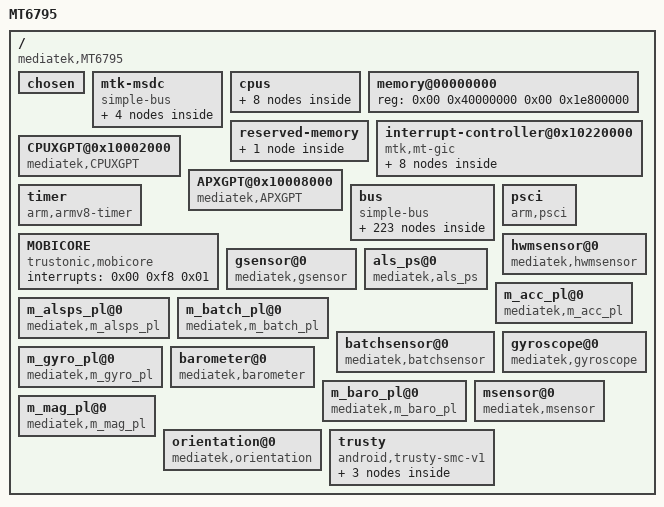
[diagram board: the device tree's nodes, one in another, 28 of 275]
/dts-v1/;

/ {
	model = "MT6795";
	compatible = "mediatek,MT6795";
	interrupt-parent = < 0x01 >;
	#address-cells = < 0x02 >;
	#size-cells = < 0x02 >;

	chosen {
		bootargs = "console=tty0 console=ttyMT0,921600n1 root=/dev/ram initrd=0x44000000,0x300000 loglevel=8";
	};

	mtk-msdc {
		compatible = "simple-bus";
		#address-cells = < 0x01 >;
		#size-cells = < 0x01 >;
		ranges = < 0x00 0x00 0x00 0xffffffff >;

		MSDC0@0x11230000 {
			compatible = "mediatek,MSDC0";
			reg = < 0x11230000 0x10000 0x10001e84 0x02 >;
			interrupts = < 0x00 0x4f 0x08 >;
		};

		MSDC1@0x11240000 {
			compatible = "mediatek,MSDC1";
			reg = < 0x11240000 0x10000 0x10001e84 0x02 >;
			interrupts = < 0x00 0x50 0x08 >;
		};

		MSDC2@0x11250000 {
			compatible = "mediatek,MSDC2";
			reg = < 0x11250000 0x10000 0x10001e84 0x02 >;
			interrupts = < 0x00 0x51 0x08 >;
		};

		MSDC3@0x11260000 {
			compatible = "mediatek,MSDC3";
			reg = < 0x11260000 0x10000 0x10001e84 0x02 >;
			interrupts = < 0x00 0x52 0x08 >;
		};
	};

	cpus {
		#address-cells = < 0x01 >;
		#size-cells = < 0x00 >;

		cpu@0 {
			device_type = "cpu";
			compatible = "arm,cortex-a53";
			reg = < 0x00 >;
			enable-method = "mt-boot";
			cpu-release-addr = < 0x00 0x40000200 >;
			clock-frequency = < 0x77359400 >;
			linux,phandle = < 0x02 >;
			phandle = < 0x02 >;
		};

		cpu@1 {
			device_type = "cpu";
			compatible = "arm,cortex-a53";
			reg = < 0x01 >;
			enable-method = "mt-boot";
			cpu-release-addr = < 0x00 0x40000200 >;
			clock-frequency = < 0x77359400 >;
			linux,phandle = < 0x03 >;
			phandle = < 0x03 >;
		};

		cpu@2 {
			device_type = "cpu";
			compatible = "arm,cortex-a53";
			reg = < 0x02 >;
			enable-method = "mt-boot";
			cpu-release-addr = < 0x00 0x40000200 >;
			clock-frequency = < 0x77359400 >;
			linux,phandle = < 0x04 >;
			phandle = < 0x04 >;
		};

		cpu@3 {
			device_type = "cpu";
			compatible = "arm,cortex-a53";
			reg = < 0x03 >;
			enable-method = "mt-boot";
			cpu-release-addr = < 0x00 0x40000200 >;
			clock-frequency = < 0x77359400 >;
			linux,phandle = < 0x05 >;
			phandle = < 0x05 >;
		};

		cpu@4 {
			device_type = "cpu";
			compatible = "arm,cortex-a53";
			reg = < 0x100 >;
			enable-method = "mt-boot";
			cpu-release-addr = < 0x00 0x40000200 >;
			clock-frequency = < 0x77359400 >;
			linux,phandle = < 0x06 >;
			phandle = < 0x06 >;
		};

		cpu@5 {
			device_type = "cpu";
			compatible = "arm,cortex-a53";
			reg = < 0x101 >;
			enable-method = "mt-boot";
			cpu-release-addr = < 0x00 0x40000200 >;
			clock-frequency = < 0x77359400 >;
			linux,phandle = < 0x07 >;
			phandle = < 0x07 >;
		};

		cpu@6 {
			device_type = "cpu";
			compatible = "arm,cortex-a53";
			reg = < 0x102 >;
			enable-method = "mt-boot";
			cpu-release-addr = < 0x00 0x40000200 >;
			clock-frequency = < 0x77359400 >;
			linux,phandle = < 0x08 >;
			phandle = < 0x08 >;
		};

		cpu@7 {
			device_type = "cpu";
			compatible = "arm,cortex-a53";
			reg = < 0x103 >;
			enable-method = "mt-boot";
			cpu-release-addr = < 0x00 0x40000200 >;
			clock-frequency = < 0x77359400 >;
			linux,phandle = < 0x09 >;
			phandle = < 0x09 >;
		};
	};

	memory@00000000 {
		device_type = "memory";
		reg = < 0x00 0x40000000 0x00 0x1e800000 >;
	};

	reserved-memory {
		#address-cells = < 0x02 >;
		#size-cells = < 0x02 >;
		ranges;

		reserve-memory-ccci_md1 {
			compatible = "reserve-memory-ccci_md1";
			no-map;
			size = < 0x00 0x5200000 >;
			alignment = < 0x00 0x2000000 >;
			alloc-ranges = < 0x00 0x40000000 0x00 0xc0000000 >;
		};
	};

	interrupt-controller@0x10220000 {
		compatible = "mtk,mt-gic";
		#interrupt-cells = < 0x03 >;
		#address-cells = < 0x00 >;
		interrupt-controller;
		reg = < 0x00 0x10221000 0x00 0x1000 0x00 0x10222000 0x00 0x1000 0x00 0x10200620 0x00 0x1000 >;
		interrupts = < 0x01 0x09 0xf04 >;
		linux,phandle = < 0x01 >;
		phandle = < 0x01 >;

		gic-cpuif@0 {
			compatible = "arm,gic-cpuif";
			cpuif-id = < 0x00 >;
			cpu = < 0x02 >;
		};

		gic-cpuif@1 {
			compatible = "arm,gic-cpuif";
			cpuif-id = < 0x01 >;
			cpu = < 0x03 >;
		};

		gic-cpuif@2 {
			compatible = "arm,gic-cpuif";
			cpuif-id = < 0x02 >;
			cpu = < 0x04 >;
		};

		gic-cpuif@3 {
			compatible = "arm,gic-cpuif";
			cpuif-id = < 0x03 >;
			cpu = < 0x05 >;
		};

		gic-cpuif@4 {
			compatible = "arm,gic-cpuif";
			cpuif-id = < 0x04 >;
			cpu = < 0x06 >;
		};

		gic-cpuif@5 {
			compatible = "arm,gic-cpuif";
			cpuif-id = < 0x05 >;
			cpu = < 0x07 >;
		};

		gic-cpuif@6 {
			compatible = "arm,gic-cpuif";
			cpuif-id = < 0x06 >;
			cpu = < 0x08 >;
		};

		gic-cpuif@7 {
			compatible = "arm,gic-cpuif";
			cpuif-id = < 0x07 >;
			cpu = < 0x09 >;
		};
	};

	CPUXGPT@0x10002000 {
		compatible = "mediatek,CPUXGPT";
		reg = < 0x00 0x10200000 0x00 0x1000 >;
		interrupts = < 0x00 0x40 0x04 0x00 0x41 0x04 0x00 0x42 0x04 0x00 0x43 0x04 0x00 0x44 0x04 0x00 0x45 0x04 0x00 0x46 0x04 0x00 0x47 0x04 >;
	};

	APXGPT@0x10008000 {
		compatible = "mediatek,APXGPT";
		reg = < 0x00 0x10008000 0x00 0x1000 >;
		interrupts = < 0x00 0x98 0x08 >;
		clock-frequency = < 0xc65d40 >;
	};

	timer {
		compatible = "arm,armv8-timer";
		interrupts = < 0x01 0x0d 0x08 0x01 0x0e 0x08 0x01 0x0b 0x08 0x01 0x0a 0x08 >;
		clock-frequency = < 0xc65d40 >;
	};

	bus {
		compatible = "simple-bus";
		#address-cells = < 0x01 >;
		#size-cells = < 0x01 >;
		ranges = < 0x00 0x00 0x00 0xffffffff >;

		CKSYS@0x10000000 {
			compatible = "mediatek,CKSYS";
			reg = < 0x10000000 0x1000 >;
		};

		usb2jtag@10000000 {
			compatible = "mediatek,mt6795-usb2jtag";
			reg = < 0x10001000 0x1000 0x11280000 0x1000 0x11290000 0x1000 >;
		};

		INFRACFG_AO@0x10001000 {
			compatible = "mediatek,INFRACFG_AO";
			reg = < 0x10001000 0x1000 >;
		};

		FHCTL@0x10209F00 {
			compatible = "mediatek,FHCTL";
			reg = < 0x10209f00 0x100 >;
		};

		PERICFG@0x10003000 {
			compatible = "mediatek,PERICFG";
			reg = < 0x10003000 0x1000 >;
		};

		DRAMC0@0x10004000 {
			compatible = "mediatek,DRAMC0";
			reg = < 0x10004000 0x1000 >;
			interrupts = < 0x00 0x95 0x02 >;
		};

		GPIO@0x10005000 {
			compatible = "mediatek,GPIO";
			reg = < 0x10005000 0x1000 >;
		};

		SLEEP@0x10006000 {
			compatible = "mediatek,SLEEP";
			reg = < 0x10006000 0x1000 >;
			interrupts = < 0x00 0xa3 0x08 0x00 0xa4 0x08 0x00 0xa5 0x08 0x00 0xa6 0x08 0x00 0xa7 0x08 0x00 0xa8 0x08 0x00 0xa9 0x08 0x00 0xaa 0x08 >;
		};

		TOPRGU@0x10007000 {
			compatible = "mediatek,TOPRGU";
			reg = < 0x10007000 0x1000 >;
			interrupts = < 0x00 0x80 0x02 >;
		};

		hacc@0x1000A000 {
			compatible = "mediatek,hacc";
			reg = < 0x1000a000 0x1000 >;
			interrupts = < 0x00 0xac 0x08 >;
		};

		EINTC@0x1000B000 {
			compatible = "mtk,mt-eic";
			reg = < 0x1000b000 0x1000 >;
			interrupts = < 0x00 0x99 0x04 >;
			max_deint_cnt = < 0x04 >;
			deint_possible_irq = < 0xbd 0xbe 0xbf 0xc0 >;
			#interrupt-cells = < 0x02 >;
			interrupt-controller;
			max_eint_num = < 0xc0 >;
			mapping_table_entry = < 0x00 >;
			linux,phandle = < 0x0a >;
			phandle = < 0x0a >;

			ACCDET@0 {
				compatible = "mediatek, ACCDET-eint";
				interrupt-parent = < 0x0a >;
				interrupts = < 0x00 0x08 >;
				debounce = < 0x00 0x3e800 >;
			};

			MHALL@1 {
				compatible = "mediatek, MHALL-eint";
				interrupt-parent = < 0x0a >;
				interrupts = < 0x01 0x08 >;
				debounce = < 0x01 0x3e800 >;
			};

			CC_DECODER@2 {
				compatible = "mediatek, CC_DECODER-eint";
				interrupt-parent = < 0x0a >;
				interrupts = < 0x02 0x02 >;
				debounce = < 0x02 0x00 >;
			};

			IRQ_NFC@3 {
				compatible = "mediatek, IRQ_NFC-eint";
				interrupt-parent = < 0x0a >;
				interrupts = < 0x03 0x04 >;
				debounce = < 0x03 0x00 >;
			};

			WIFI@4 {
				compatible = "mediatek, WIFI-eint";
				interrupt-parent = < 0x0a >;
				interrupts = < 0x04 0x08 >;
				debounce = < 0x04 0x00 >;
			};

			TOUCH_PANEL@6 {
				compatible = "mediatek, TOUCH_PANEL-eint";
				interrupt-parent = < 0x0a >;
				interrupts = < 0x06 0x02 >;
				debounce = < 0x06 0x00 >;
			};

			EXT_BUCK_OC@7 {
				compatible = "mediatek, EXT_BUCK_OC-eint";
				interrupt-parent = < 0x0a >;
				interrupts = < 0x07 0x08 >;
				debounce = < 0x07 0x00 >;
			};

			ALS@8 {
				compatible = "mediatek, ALS-eint";
				interrupt-parent = < 0x0a >;
				interrupts = < 0x08 0x08 >;
				debounce = < 0x08 0x00 >;
			};

			MSE@12 {
				compatible = "mediatek, MSE-eint";
				interrupt-parent = < 0x0a >;
				interrupts = < 0x0c 0x04 >;
				debounce = < 0x0c 0x00 >;
			};

			GYRO@105 {
				compatible = "mediatek, GYRO-eint";
				interrupt-parent = < 0x0a >;
				interrupts = < 0x69 0x02 >;
				debounce = < 0x69 0x00 >;
			};

			DSI_TE_1@107 {
				compatible = "mediatek, DSI_TE_1-eint";
				interrupt-parent = < 0x0a >;
				interrupts = < 0x6b 0x01 >;
				debounce = < 0x6b 0x00 >;
			};

			MHL@134 {
				compatible = "mediatek, MHL-eint";
				interrupt-parent = < 0x0a >;
				interrupts = < 0x86 0x08 >;
				debounce = < 0x86 0x00 >;
			};
		};

		SMI_COMMON@0x14022000 {
			compatible = "mediatek,SMI_COMMON";
			reg = < 0x14022000 0x1000 0x14021000 0x1000 0x16010000 0x1000 0x15001000 0x1000 0x18001000 0x1000 0x17002000 0x1000 >;
		};

		E3TCM@0x1000C000 {
			compatible = "mediatek,E3TCM";
			reg = < 0x1000c000 0x1000 >;
		};

		PMIC_WRAP@0x1000D000 {
			compatible = "mediatek,PMIC_WRAP";
			reg = < 0x1000d000 0x1000 >;
			interrupts = < 0x00 0xa1 0x04 >;
		};

		DEVAPC_AO@0x1000E000 {
			compatible = "mediatek,DEVAPC_AO";
			reg = < 0x1000e000 0x1000 >;
		};

		DDRPHY@0x1000F000 {
			compatible = "mediatek,DDRPHY";
			reg = < 0x1000f000 0x1000 >;
		};

		KP@0x10010000 {
			compatible = "mediatek,KP";
			reg = < 0x10010000 0x1000 >;
			interrupts = < 0x00 0xa2 0x02 >;
		};

		DRAMC1@0x10011000 {
			compatible = "mediatek,DRAMC1";
			reg = < 0x10011000 0x1000 >;
		};

		DDRPHY1@0x10012000 {
			compatible = "mediatek,DDRPHY1";
			reg = < 0x10012000 0x1000 >;
		};

		BAT_METTER {
			compatible = "mediatek,bat_meter";
		};

		BAT_NOTIFY {
			compatible = "mediatek,bat_notify";
		};

		SCP_SRAM@0x10020000 {
			compatible = "mediatek,SCP_SRAM";
			reg = < 0x10020000 0x40000 0x10060000 0x80000 >;
		};

		SCP_CFGREG@0x10050000 {
			compatible = "mediatek,SCP_CFGREG";
			reg = < 0x10050000 0x400 >;
			interrupts = < 0x00 0xae 0x04 >;
		};

		DBGAPB_BASE@0x1011A000 {
			compatible = "mediatek,DBGAPB_BASE";
			reg = < 0x1011a000 0x100 >;
		};

		DBG_ETB@0x10100000 {
			compatible = "mediatek,DBG_ETB";
			reg = < 0x10111000 0x10000 0x10113000 0x10000 0x10114000 0x10000 0x1011a000 0x10000 >;
		};

		DBG_ETM {
			compatible = "mediatek,DBG_ETM";
			num = < 0x08 >;
			reg = < 0x10840000 0x1000 0x10940000 0x1000 0x10a40000 0x1000 0x10b40000 0x1000 0x10c40000 0x1000 0x10d40000 0x1000 0x10e40000 0x1000 0x10f40000 0x1000 >;
		};

		MCUCFG@0x10200000 {
			compatible = "mediatek,MCUCFG";
			reg = < 0x10200000 0x1000 >;
			interrupts = < 0x00 0x47 0x04 >;
		};

		INFRACFG@0x10201000 {
			compatible = "mediatek,INFRACFG";
			reg = < 0x10201000 0x1000 >;
			interrupts = < 0x00 0x8b 0x01 >;
		};

		SRAMROM@0x10202000 {
			compatible = "mediatek,SRAMROM";
			reg = < 0x10202000 0x1000 >;
		};

		EMI@0x10203000 {
			compatible = "mediatek,EMI";
			reg = < 0x10203000 0x1000 >;
			interrupts = < 0x00 0x88 0x08 >;
		};

		SYS_CIRQ@0x10204000 {
			compatible = "mediatek,SYS_CIRQ";
			reg = < 0x10204000 0x1000 >;
			interrupts = < 0x00 0xf0 0x08 >;
			cirq_num = < 0xa8 >;
			spi_start_offset = < 0x48 >;
		};

		M4U@0x10205000 {
			cell-index = < 0x00 >;
			compatible = "mediatek,M4U";
			reg = < 0x10205000 0x1000 >;
			interrupts = < 0x00 0x93 0x08 >;
		};

		EFUSEC@0x10206000 {
			compatible = "mediatek,EFUSEC";
			reg = < 0x10206000 0x1000 >;
		};

		DEVAPC@0x10207000 {
			compatible = "mediatek,DEVAPC";
			reg = < 0x10207000 0x1000 >;
			interrupts = < 0x00 0x86 0x08 >;
		};

		BUS_DBG@0x10208000 {
			compatible = "mediatek,BUS_DBG";
			reg = < 0x10208000 0x1000 >;
			interrupts = < 0x00 0x85 0x08 >;
		};

		APMIXED@0x10209000 {
			compatible = "mediatek,APMIXED";
			reg = < 0x10209000 0x1000 >;
		};

		AP_CCIF0@0x1020A000 {
			compatible = "mediatek,AP_CCIF0";
			reg = < 0x1020a000 0x1000 >;
			interrupts = < 0x00 0x8c 0x08 >;
		};

		MD_CCIF0@0x1020B000 {
			compatible = "mediatek,MD_CCIF0";
			reg = < 0x1020b000 0x1000 >;
		};

		GPIO1@0x1020C000 {
			compatible = "mediatek,GPIO1";
			reg = < 0x1020c000 0x1000 >;
		};

		INFRA_MBIST@0x1020D000 {
			compatible = "mediatek,INFRA_MBIST";
			reg = < 0x1020d000 0x1000 >;
		};

		DRAMC_NAO@0x1020E000 {
			compatible = "mediatek,DRAMC_NAO";
			reg = < 0x1020e000 0x1000 >;
		};

		TRNG@0x1020F000 {
			compatible = "mediatek,TRNG";
			reg = < 0x1020f000 0x1000 >;
			interrupts = < 0x00 0x8d 0x08 >;
		};

		GCPU@0x10210000 {
			compatible = "mediatek,gcpu";
			reg = < 0x10210000 0x1000 >;
			interrupts = < 0x00 0x96 0x08 >;
		};

		GCP_NS@0x10211000 {
			compatible = "mediatek,GCP_NS";
			reg = < 0x10211000 0x1000 >;
		};

		gce@10212000 {
			compatible = "mediatek,gce";
			reg = < 0x10212000 0x1000 >;
			interrupts = < 0x00 0x8f 0x08 0x00 0x90 0x08 >;
			disp_mutex_reg = < 0x14020000 0x1000 >;
			g3d_config_base = < 0x13000000 0x00 0xffff0000 >;
			mmsys_config_base = < 0x14000000 0x01 0xffff0000 >;
			disp_dither_base = < 0x14010000 0x02 0xffff0000 >;
			mm_na_base = < 0x14020000 0x03 0xffff0000 >;
			imgsys_base = < 0x15000000 0x04 0xffff0000 >;
			vdec_gcon_base = < 0x16000000 0x05 0xffff0000 >;
			venc_gcon_base = < 0x17000000 0x06 0xffff0000 >;
			conn_peri_base = < 0x18000000 0x07 0xffff0000 >;
			topckgen_base = < 0x10000000 0x08 0xffff0000 >;
			kp_base = < 0x10010000 0x09 0xffff0000 >;
			scp_sram_base = < 0x10020000 0x0a 0xffff0000 >;
			infra_na3_base = < 0x10030000 0x0b 0xffff0000 >;
			infra_na4_base = < 0x10040000 0x0c 0xffff0000 >;
			scp_base = < 0x10050000 0x0d 0xffff0000 >;
			mcucfg_base = < 0x10200000 0x0e 0xffff0000 >;
			gcpu_base = < 0x10210000 0x0f 0xffff0000 >;
			usb0_base = < 0x11200000 0x10 0xffff0000 >;
			usb_sif_base = < 0x11210000 0x11 0xffff0000 >;
			audio_base = < 0x11220000 0x12 0xffff0000 >;
			msdc0_base = < 0x11230000 0x13 0xffff0000 >;
			msdc1_base = < 0x11240000 0x14 0xffff0000 >;
			msdc2_base = < 0x11250000 0x15 0xffff0000 >;
			msdc3_base = < 0x11260000 0x16 0xffff0000 >;
			mdp_rdma0_sof = < 0x00 >;
			mdp_rdma1_sof = < 0x01 >;
			mdp_dsi0_te_sof = < 0x02 >;
			mdp_dsi1_te_sof = < 0x03 >;
			mdp_mvw_sof = < 0x04 >;
			mdp_tdshp0_sof = < 0x05 >;
			mdp_tdshp1_sof = < 0x06 >;
			mdp_wdma_sof = < 0x07 >;
			mdp_wrot0_sof = < 0x08 >;
			mdp_wrot1_sof = < 0x09 >;
			mdp_crop_sof = < 0x0a >;
			disp_ovl0_sof = < 0x0b >;
			disp_ovl1_sof = < 0x0c >;
			disp_rdma0_sof = < 0x0d >;
			disp_rdma1_sof = < 0x0e >;
			disp_rdma2_sof = < 0x0f >;
			disp_wdma0_sof = < 0x10 >;
			disp_wdma1_sof = < 0x11 >;
			disp_color0_sof = < 0x12 >;
			disp_color1_sof = < 0x13 >;
			disp_aal_sof = < 0x14 >;
			disp_gamma_sof = < 0x15 >;
			disp_ufoe_sof = < 0x16 >;
			disp_pwm0_sof = < 0x17 >;
			disp_pwm1_sof = < 0x18 >;
			disp_od_sof = < 0x19 >;
			mdp_rdma0_frame_done = < 0x1a >;
			mdp_rdma1_frame_done = < 0x1b >;
			mdp_rsz0_frame_done = < 0x1c >;
			mdp_rsz1_frame_done = < 0x1d >;
			mdp_rsz2_frame_done = < 0x1e >;
			mdp_tdshp0_frame_done = < 0x1f >;
			mdp_tdshp1_frame_done = < 0x20 >;
			mdp_wdma_frame_done = < 0x21 >;
			mdp_wrot0_write_frame_done = < 0x22 >;
			mdp_wrot0_read_frame_done = < 0x23 >;
			mdp_wrot1_write_frame_done = < 0x24 >;
			mdp_wrot1_read_frame_done = < 0x25 >;
			mdp_crop_frame_done = < 0x26 >;
			disp_ovl0_frame_done = < 0x27 >;
			disp_ovl1_frame_done = < 0x28 >;
			disp_rdma0_frame_done = < 0x29 >;
			disp_rdma1_frame_done = < 0x2a >;
			disp_rdma2_frame_done = < 0x2b >;
			disp_wdma0_frame_done = < 0x2c >;
			disp_wdma1_frame_done = < 0x2d >;
			disp_color0_frame_done = < 0x2e >;
			disp_color1_frame_done = < 0x2f >;
			disp_aal_frame_done = < 0x30 >;
			disp_gamma_frame_done = < 0x31 >;
			disp_ufoe_frame_done = < 0x32 >;
			disp_dpi0_frame_done = < 0x33 >;
			stream_done_0 = < 0x34 >;
			stream_done_1 = < 0x35 >;
			stream_done_2 = < 0x36 >;
			stream_done_3 = < 0x37 >;
			stream_done_4 = < 0x38 >;
			stream_done_5 = < 0x39 >;
			stream_done_6 = < 0x3a >;
			stream_done_7 = < 0x3b >;
			stream_done_8 = < 0x3c >;
			stream_done_9 = < 0x3d >;
			buf_underrun_event_0 = < 0x3e >;
			buf_underrun_event_1 = < 0x3f >;
			buf_underrun_event_2 = < 0x40 >;
			isp_frame_done_p2_2 = < 0x81 >;
			isp_frame_done_p2_1 = < 0x82 >;
			isp_frame_done_p2_0 = < 0x83 >;
			isp_frame_done_p1_1 = < 0x84 >;
			isp_frame_done_p1_0 = < 0x85 >;
			camsv_2_pass1_done = < 0x86 >;
			camsv_1_pass1_done = < 0x87 >;
			seninf_cam1_2_3_fifo_full = < 0x88 >;
			seninf_cam0_fifo_full = < 0x89 >;
			jpgenc_pass2_done = < 0x101 >;
			jpgenc_pass1_done = < 0x102 >;
			jpgdec_done = < 0x103 >;
			apxgpt2_count = < 0x10008028 >;
		};

		CQDMA@0x10212c00 {
			compatible = "mediatek,CQDMA";
			reg = < 0x10212c00 0x1000 >;
			interrupts = < 0x00 0x8f 0x08 >;
			nr_channel = < 0x01 >;
		};

		DRAMC1_NAO@0x10213000 {
			compatible = "mediatek,DRAMC1_NAO";
			reg = < 0x10213000 0x1000 >;
		};

		PERISYS_IOMMU@0x10214000 {
			cell-index = < 0x01 >;
			compatible = "mediatek,PERISYS_IOMMU";
			reg = < 0x10214000 0x1000 >;
			interrupts = < 0x00 0x91 0x08 >;
		};

		MIPI_TX0@0x10215000 {
			compatible = "mediatek,MIPI_TX0";
			reg = < 0x10215000 0x1000 >;
		};

		MIPI_TX1@0x10216000 {
			compatible = "mediatek,MIPI_TX1";
			reg = < 0x10216000 0x1000 >;
		};

		MIPI_RX_ANA_CSI0@0x10217000 {
			compatible = "mediatek,MIPI_RX_ANA_CSI0";
			reg = < 0x10217000 0x1000 >;
		};

		MIPI_RX_ANA_CSI1@0x10218000 {
			compatible = "mediatek,MIPI_RX_ANA_CSI1";
			reg = < 0x10218000 0x1000 >;
		};

		MIPI_RX_ANA_CSI2@0x10219000 {
			compatible = "mediatek,MIPI_RX_ANA_CSI2";
			reg = < 0x10219000 0x1000 >;
		};

		CA9@0x10220000 {
			compatible = "mediatek,CA9";
			reg = < 0x10220000 0x8000 >;
		};

		DBGAPB@0x10100000 {
			compatible = "mediatek,DBGAPB";
			reg = < 0x10100000 0x01 >;
			interrupts = < 0x00 0x84 0x08 >;
		};

		CCI400@0x10390000 {
			compatible = "mediatek,CCI400";
			reg = < 0x10390000 0x10000 >;
		};

		CPU_DBGAPB {
			compatible = "mediatek,DBG_DEBUG";
			num = < 0x08 >;
			reg = < 0x10810000 0x1000 0x10910000 0x1000 0x10a10000 0x1000 0x10b10000 0x1000 0x10c10000 0x1000 0x10d10000 0x1000 0x10e10000 0x1000 0x10f10000 0x1000 >;
		};

		AP_DMA@0x11000000 {
			compatible = "mediatek,AP_DMA";
			reg = < 0x11000000 0x1000 >;
			interrupts = < 0x00 0x6e 0x08 >;
		};

		AUXADC@0x11001000 {
			compatible = "mediatek,AUXADC";
			reg = < 0x11001000 0x1000 >;
			interrupts = < 0x00 0x4c 0x02 >;
		};

		AP_DMA_UART0_TX@0x11000380 {
			compatible = "mediatek,AP_DMA_UART0_TX";
			reg = < 0x11000380 0x80 >;
			interrupts = < 0x00 0x67 0x08 >;
		};

		AP_DMA_UART0_RX@0x11000400 {
			compatible = "mediatek,AP_DMA_UART0_RX";
			reg = < 0x11000400 0x80 >;
			interrupts = < 0x00 0x68 0x08 >;
		};

		AP_DMA_UART1_TX@0x11000480 {
			compatible = "mediatek,AP_DMA_UART1_TX";
			reg = < 0x11000480 0x80 >;
			interrupts = < 0x00 0x69 0x08 >;
		};

		AP_DMA_UART1_RX@0x11000500 {
			compatible = "mediatek,AP_DMA_UART1_RX";
			reg = < 0x11000500 0x80 >;
			interrupts = < 0x00 0x6a 0x08 >;
		};

		AP_DMA_UART2_TX@0x11000580 {
			compatible = "mediatek,AP_DMA_UART2_TX";
			reg = < 0x11000580 0x80 >;
			interrupts = < 0x00 0x6b 0x08 >;
		};

		AP_DMA_UART2_RX@0x11000600 {
			compatible = "mediatek,AP_DMA_UART2_RX";
			reg = < 0x11000600 0x80 >;
			interrupts = < 0x00 0x6c 0x08 >;
		};

		AP_DMA_UART3_TX@0x11000680 {
			compatible = "mediatek,AP_DMA_UART3_TX";
			reg = < 0x11000680 0x80 >;
			interrupts = < 0x00 0x6d 0x08 >;
		};

		AP_DMA_UART3_RX@0x11000700 {
			compatible = "mediatek,AP_DMA_UART3_RX";
			reg = < 0x11000700 0x80 >;
			interrupts = < 0x00 0x6e 0x08 >;
		};

		AP_UART0@0x11002000 {
			cell-index = < 0x00 >;
			compatible = "mediatek,AP_UART0";
			reg = < 0x11002000 0x1000 >;
			interrupts = < 0x00 0x5b 0x08 >;
		};

		AP_UART1@0x11003000 {
			cell-index = < 0x01 >;
			compatible = "mediatek,AP_UART1";
			reg = < 0x11003000 0x1000 >;
			interrupts = < 0x00 0x5c 0x08 >;
		};

		AP_UART2@0x11004000 {
			cell-index = < 0x02 >;
			compatible = "mediatek,AP_UART2";
			reg = < 0x11004000 0x1000 >;
			interrupts = < 0x00 0x5d 0x08 >;
		};

		AP_UART3@0x11005000 {
			cell-index = < 0x03 >;
			compatible = "mediatek,AP_UART3";
			reg = < 0x11005000 0x1000 >;
			interrupts = < 0x00 0x5e 0x08 >;
		};

		PWM@0x11006000 {
			compatible = "mediatek,PWM";
			reg = < 0x11006000 0x1000 >;
			interrupts = < 0x00 0x4d 0x08 >;
		};

		I2C0@0x11007000 {
			compatible = "mediatek,I2C0";
			cell-index = < 0x00 >;
			reg = < 0x11007000 0x1000 >;
			interrupts = < 0x00 0x54 0x08 >;
			def_speed = < 0x64 >;
		};

		I2C1@0x11008000 {
			compatible = "mediatek,I2C1";
			cell-index = < 0x01 >;
			reg = < 0x11008000 0x1000 >;
			interrupts = < 0x00 0x55 0x08 >;
			def_speed = < 0x6e >;
		};

		I2C2@0x11009000 {
			compatible = "mediatek,I2C2";
			cell-index = < 0x02 >;
			reg = < 0x11009000 0x1000 >;
			interrupts = < 0x00 0x56 0x08 >;
			def_speed = < 0x78 >;

			bq25890@6A {
				compatible = "ti,bq2589x-1";
				reg = < 0x6a >;
				ti,bq2589x,vbus-volt-high-level = < 0x21fc >;
				ti,bq2589x,vbus-volt-low-level = < 0x1130 >;
				ti,bq2589x,vbat-min-volt-to-tuneup = < 0xbb8 >;
			};

			bq25892@6B {
				compatible = "ti,bq2589x-2";
				reg = < 0x6b >;
			};

			synaptics-tpd@4b {
				compatible = "synaptics,synaptics-tpd";
				reg = < 0x4b >;
			};

			atmel_mxt_ts@4a {
				compatible = "atmel,atmel_mxt_ts";
				reg = < 0x4a >;
				atmel,cfg_name = "30AA.cfg";
				atmel,fw_version = "30AA.fw";
				atmel,input_name = "atmel_mxt_ts";
				linux,gpio-keymap = < 0x9e 0x244 0xac >;

				atmel,cfg_1 {
					atmel,type = < 0x01 >;
					atmel,family-id = < 0xa4 >;
					atmel,variant-id = < 0x02 >;
					atmel,version = < 0x30 >;
					atmel,build = < 0xaa >;
					atmel,config-year = < 0x0f >;
					atmel,config-month = < 0x0b >;
					atmel,config-date = < 0x03 >;
					atmel,config = < 0x250000 0x820000 0x00 0x00 0x00 0x00 0x00 0x00 0x00 0x00 0x00 0x00 0x00 0x00 0x00 0x00 0x00 0x00 0x00 0x00 0x00 0x00 0x00 0x00 0x00 0x00 0x00 0x00 0x00 0x00 0x00 0x00 0x00 0x00 0x2c0000 0x10000 0x5000000 0xbff0000 0x00 0xff 0x60000 0x70000 0x00 0x4400 0x4900 0x00 0x00 0x00 0x00 0x00 0x00 0x00 0x00 0x00 0x00 0x00 0x00 0x00 0x00 0x00 0x00 0x00 0x00 0x260000 0x400030 0xaa0f0b03 0x00 0x00 0x00 0x00 0x00 0x00 0x00 0x00 0x00 0x00 0x00 0x00 0x00 0x00 0x47 0xc8 0x00 0x00 0x00 0x00 0x00 0x00 0x00 0x00 0x00 0x00 0x00 0x00 0x00 0x00 0x00 0x00 0x00 0x00 0x00 0x00 0x00 0x00 0x00 0x00 0x00 0x00 0x00 0x00 0x00 0x00 0x00 0x00 0x00 0x00 0x00 0x00 0x00 0x00 0x00 0x00 0x00 0x00 0x00 0x00 0x00 0x00 0x00 0x00 0x00 0x00 0x6e0000 0x28d908 0xa10a190a 0xe90b590a 0xa90ba109 0x890bc909 0x21099908 0x49088906 0x5106d103 0x1000100 0x1000100 0x100006e 0x10028 0x1000100 0x1000100 0x1000100 0x1000100 0x1000100 0x1000100 0x1000100 0x1000100 0x1000100 0x1000100 0x6e0002 0x280100 0x1000100 0x1000100 0x1000100 0x1000100 0x1000100 0x1000100 0x1000100 0x1000100 0x1000100 0x100006e 0x30028 0xc108210a 0xc90a290b 0x710b110b 0xf909d10b 0x1909e909 0x9907e908 0xd905e906 0xd1030100 0x1000100 0x1000100 0x6e0004 0x280000 0x00 0x00 0x00 0x00 0x00 0x00 0x00 0x00 0x00 0x6e 0x50028 0x00 0x00 0x00 0x00 0x00 0x00 0x00 0x00 0x00 0x00 0x6e0006 0x280b03 0xfb02fb02 0xf302f302 0xf302fb02 0xeb02f302 0xfb020b03 0xb031b03 0x1b033303 0x3000300 0x3000300 0x300006e 0x70028 0x3000300 0x3000300 0x3000300 0x3000300 0x3000300 0x3000300 0x3000300 0x3000300 0x3000300 0x3000300 0x6e0008 0x280300 0x3000300 0x3000300 0x3000300 0x3000300 0x3000300 0x3000300 0x3000300 0x3000300 0x3000300 0x3000007 0x05 0xffff1e40 0x800 0xf2d 0x140a00 0xff0100 0xb0101 0x102000f 0x0b 0x831a0f01 0x3000832 0x2000000 0x12000000 0x2000000 0x13000000 0x6000000 0x00 0x19000000 0x10030048 0x71085248 0x710852ff 0x70177017 0x2800 0x731 0x3030000 0x1002a 0x0e 0x21008032 0xff05001e 0x502c800 0x2b 0x11 0x00 0x00 0x00 0x00 0x2e00 0xc00 0x180801 0x5000 0x1000000 0x2f000000 0x2f000000 0x00 0x00 0x00 0x00 0x00 0x00 0x00 0x00 0x00 0x00 0x00 0x380000 0x240000 0x240000 0x00 0x00 0x00 0x00 0x00 0x00 0x00 0x3d 0x05 0x00 0x3d00 0x1000500 0x00 0x3d0002 0x50000 0x00 0x3d000300 0x5000000 0x3d 0x40005 0x00 0x3d00 0x5000500 0x00 0x410000 0x17810a 0x00 0x00 0xa000000 0x21 0x00 0x4100 0x1001700 0x00 0x00 0x00 0x00 0x00 0x41 0x20017 0x00 0x00 0x00 0x00 0x00 0x00 0x46000000 0xa000000 0x00 0x00 0x46000100 0xa000000 0x00 0x00 0x46000200 0xa000000 0x00 0x00 0x46000300 0xa000000 0x00 0x00 0x46000400 0xa000000 0x00 0x00 0x46000500 0xa000000 0x00 0x00 0x46000600 0xa000000 0x00 0x00 0x46000700 0xa000000 0x00 0x00 0x46000800 0xa000000 0x00 0x00 0x46000900 0xa000000 0x00 0x00 0x46000a00 0xa000000 0x00 0x00 0x46000b00 0xa000000 0x00 0x00 0x46000c00 0xa000000 0x00 0x00 0x46000d00 0xa000000 0x00 0x00 0x46000e00 0xa000000 0x00 0x00 0x46000f00 0xa000000 0x00 0x01 0x46001000 0xa000000 0x00 0x00 0x46001100 0xa000000 0x00 0x00 0x46001200 0xa000000 0x00 0x00 0x46001300 0xa000000 0x00 0x00 0x46001400 0xa000000 0x00 0x00 0x46001500 0xa000000 0x00 0x00 0x46001600 0xa000000 0x00 0x00 0x46001700 0xa000000 0x00 0x00 0x46001800 0xa000000 0x00 0x00 0x46001900 0xa000000 0x00 0x00 0x46001a00 0xa000000 0x00 0x00 0x46001b00 0xa000000 0x00 0x00 0x46001c00 0xa000000 0x00 0x00 0x46001d00 0xa000000 0x00 0x00 0x46001e00 0xa000000 0x00 0x00 0x46001f00 0xa000000 0x00 0x00 0x46002000 0xa000000 0x00 0x00 0x46002100 0xa000000 0x00 0x00 0x46002200 0xa000000 0x00 0x00 0x46002300 0xa000000 0x00 0x00 0x46002400 0xa000000 0x00 0x00 0x46002500 0xa000000 0x00 0x00 0x46002600 0xa000000 0x00 0x00 0x46002700 0xa000000 0x00 0x00 0x48000000 0x59fd0000 0x100050a 0x505070a 0x14020420 0x500d0c36 0x5000000 0x0c 0xc0c0c0c 0xc0c0c0c 0xc000019 0x1060e 0x1d252e10 0x10101010 0x10101010 0x10000f23 0x110f060e 0x1d252e40 0x40404040 0x40404040 0x40001c00 0x11000803 0x3020000 0x4d 0x02 0x4e 0x0c 0x84040000 0x19001900 0x8c000000 0x4f0000 0x40000 0x4f 0x10004 0x00 0x4f0002 0x40000 0x50 0x0e 0x3227d3c 0xf45000f 0x1010000 0x51 0x12 0x00 0x00 0x00 0x00 0x51 0x10012 0x00 0x00 0x00 0x00 0x54 0x04 0x00 0x5d0000 0x1e0f00 0x370400 0x7f0700 0x00 0x00 0x6400 0x6400011e 0x11e0000 0x630000 0xc0000 0x00 0x00 0x64 0x3e 0x83300006 0xa88 0x1a2d00 0x7f0726 0x21105a00 0xf2d0303 0x37041540 0xc07280f 0x14000014 0x3c140001 0x101000a 0x42dc1e05 0x10000 0x39b21 0x00 0x65 0x20 0x00 0x00 0x00 0x00 0x00 0x00 0x00 0x00 0x680000 0xb0100 0x460f2303 0x181e0f0f 0x3006c00 0x4b00 0x00 0x00 0x00 0x00 0x00 0x00 0x00 0x00 0x00 0x00 0x00 0x00 0x00 0x00 0x00 0x00 0x00 0x00 0x6d 0x09 0x42000500 0x00 0x3006f00 0x1e00 0x32320c 0xc0f0500 0xff000000 0x00 0x1e0033 0x32000000 0x1000000 0x6f00 0x1001e00 0x00 0x00 0x00 0x00 0x00 0x00 0x1000000 0x6f00 0x2001e00 0x32320c 0xc0f0300 0x00 0x00 0x00 0x00 0x1000000 0x7000 0x500 0x00 0x700001 0x50000 0x00 0x71000000 0x3050206 0x730000 0x140000 0x00 0x00 0x00 0x00 0x74 0xff 0x00 0x00 0x00 0x00 0x00 0x00 0x00 0x00 0x00 0x00 0x00 0x00 0x00 0x00 0x00 0x00 0x00 0x00 0x00 0x00 0x00 0x00 0x00 0x00 0x00 0x00 0x00 0x00 0x00 0x00 0x00 0x00 0x00 0x00 0x00 0x00 0x00 0x00 0x00 0x00 0x00 0x00 0x00 0x00 0x00 0x00 0x00 0x00 0x00 0x00 0x00 0x00 0x00 0x00 0x00 0x00 0x00 0x00 0x00 0x00 0x00 0x00 0x00 0x00 0x79000000 0x3000000 0x7c0000 0x70b10 0x1b41 0x64007d00 0x100 >;
				};

				atmel,cfg_2 {
					atmel,type = < 0x00 >;
					atmel,family-id = < 0xa4 >;
					atmel,variant-id = < 0x02 >;
					atmel,version = < 0x30 >;
					atmel,build = < 0xaa >;
					atmel,config-year = < 0x0f >;
					atmel,config-month = < 0x0b >;
					atmel,config-date = < 0x03 >;
					atmel,config = < 0x250000 0x820000 0x00 0x00 0x00 0x00 0x00 0x00 0x00 0x00 0x00 0x00 0x00 0x00 0x00 0x00 0x00 0x00 0x00 0x00 0x00 0x00 0x00 0x00 0x00 0x00 0x00 0x00 0x00 0x00 0x00 0x00 0x00 0x00 0x2c0000 0x10000 0x5000000 0xbff0000 0x00 0xff 0x60000 0x70000 0x00 0x4400 0x4900 0x00 0x00 0x00 0x00 0x00 0x00 0x00 0x00 0x00 0x00 0x00 0x00 0x00 0x00 0x00 0x00 0x00 0x00 0x260000 0x400030 0xaa0f0b03 0x00 0x00 0x00 0x00 0x00 0x00 0x00 0x00 0x00 0x00 0x00 0x00 0x00 0x00 0x47 0xc8 0x00 0x00 0x00 0x00 0x00 0x00 0x00 0x00 0x00 0x00 0x00 0x00 0x00 0x00 0x00 0x00 0x00 0x00 0x00 0x00 0x00 0x00 0x00 0x00 0x00 0x00 0x00 0x00 0x00 0x00 0x00 0x00 0x00 0x00 0x00 0x00 0x00 0x00 0x00 0x00 0x00 0x00 0x00 0x00 0x00 0x00 0x00 0x00 0x00 0x00 0x6e0000 0x28d908 0xa10a190a 0xe90b590a 0xa90ba109 0x890bc909 0x21099908 0x49088906 0x5106d103 0x1000100 0x1000100 0x100006e 0x10028 0x1000100 0x1000100 0x1000100 0x1000100 0x1000100 0x1000100 0x1000100 0x1000100 0x1000100 0x1000100 0x6e0002 0x280100 0x1000100 0x1000100 0x1000100 0x1000100 0x1000100 0x1000100 0x1000100 0x1000100 0x1000100 0x100006e 0x30028 0xc108210a 0xc90a290b 0x710b110b 0xf909d10b 0x1909e909 0x9907e908 0xd905e906 0xd1030100 0x1000100 0x1000100 0x6e0004 0x280000 0x00 0x00 0x00 0x00 0x00 0x00 0x00 0x00 0x00 0x6e 0x50028 0x00 0x00 0x00 0x00 0x00 0x00 0x00 0x00 0x00 0x00 0x6e0006 0x280b03 0xfb02fb02 0xf302f302 0xf302fb02 0xeb02f302 0xfb020b03 0xb031b03 0x1b033303 0x3000300 0x3000300 0x300006e 0x70028 0x3000300 0x3000300 0x3000300 0x3000300 0x3000300 0x3000300 0x3000300 0x3000300 0x3000300 0x3000300 0x6e0008 0x280300 0x3000300 0x3000300 0x3000300 0x3000300 0x3000300 0x3000300 0x3000300 0x3000300 0x3000300 0x3000007 0x05 0xffff1e40 0x800 0xf2d 0x140a00 0xff0100 0xb0101 0x102000f 0x0b 0x831a0f01 0x3000832 0x2000000 0x12000000 0x2000000 0x13000000 0x6000000 0x00 0x19000000 0x10030048 0x71085248 0x710852ff 0x70177017 0x2800 0x731 0x3030000 0x1002a 0x0e 0x21008032 0xff05001e 0x502c800 0x2b 0x11 0x00 0x00 0x00 0x00 0x2e00 0xc00 0x180801 0x5000 0x1000000 0x2f000000 0x2f000000 0x00 0x00 0x00 0x00 0x00 0x00 0x00 0x00 0x00 0x00 0x00 0x380000 0x240000 0x240000 0x00 0x00 0x00 0x00 0x00 0x00 0x00 0x3d 0x05 0x00 0x3d00 0x1000500 0x00 0x3d0002 0x50000 0x00 0x3d000300 0x5000000 0x3d 0x40005 0x00 0x3d00 0x5000500 0x00 0x410000 0x17810a 0x00 0x00 0xa000000 0x21 0x00 0x4100 0x1001700 0x00 0x00 0x00 0x00 0x00 0x41 0x20017 0x00 0x00 0x00 0x00 0x00 0x00 0x46000000 0xa000000 0x00 0x00 0x46000100 0xa000000 0x00 0x00 0x46000200 0xa000000 0x00 0x00 0x46000300 0xa000000 0x00 0x00 0x46000400 0xa000000 0x00 0x00 0x46000500 0xa000000 0x00 0x00 0x46000600 0xa000000 0x00 0x00 0x46000700 0xa000000 0x00 0x00 0x46000800 0xa000000 0x00 0x00 0x46000900 0xa000000 0x00 0x00 0x46000a00 0xa000000 0x00 0x00 0x46000b00 0xa000000 0x00 0x00 0x46000c00 0xa000000 0x00 0x00 0x46000d00 0xa000000 0x00 0x00 0x46000e00 0xa000000 0x00 0x00 0x46000f00 0xa000000 0x00 0x00 0x46001000 0xa000000 0x00 0x00 0x46001100 0xa000000 0x00 0x00 0x46001200 0xa000000 0x00 0x00 0x46001300 0xa000000 0x00 0x00 0x46001400 0xa000000 0x00 0x00 0x46001500 0xa000000 0x00 0x00 0x46001600 0xa000000 0x00 0x00 0x46001700 0xa000000 0x00 0x00 0x46001800 0xa000000 0x00 0x00 0x46001900 0xa000000 0x00 0x00 0x46001a00 0xa000000 0x00 0x00 0x46001b00 0xa000000 0x00 0x00 0x46001c00 0xa000000 0x00 0x00 0x46001d00 0xa000000 0x00 0x00 0x46001e00 0xa000000 0x00 0x00 0x46001f00 0xa000000 0x00 0x00 0x46002000 0xa000000 0x00 0x00 0x46002100 0xa000000 0x00 0x00 0x46002200 0xa000000 0x00 0x00 0x46002300 0xa000000 0x00 0x00 0x46002400 0xa000000 0x00 0x00 0x46002500 0xa000000 0x00 0x00 0x46002600 0xa000000 0x00 0x00 0x46002700 0xa000000 0x00 0x00 0x48000000 0x59fd0000 0x100050a 0x505070a 0x14020420 0x500d0c36 0x5000000 0x0c 0xc0c0c0c 0xc0c0c0c 0xc000019 0x1060e 0x1d252e10 0x10101010 0x10101010 0x10000f23 0x110f060e 0x1d252e40 0x40404040 0x40404040 0x40001c00 0x11000803 0x3020000 0x4d 0x02 0x4e 0x0c 0x84040000 0x19001900 0x8c000000 0x4f0000 0x40000 0x4f 0x10004 0x00 0x4f0002 0x40000 0x50 0x0e 0x3227d3c 0xf45000f 0x1010000 0x51 0x12 0x00 0x00 0x00 0x00 0x51 0x10012 0x00 0x00 0x00 0x00 0x54 0x04 0x00 0x5d0000 0x1e0f00 0x370400 0x7f0700 0x00 0x00 0x6400 0x6400011e 0x11e0000 0x630000 0xc0000 0x00 0x00 0x64 0x3e 0x83300006 0xa88 0x1a2d00 0x7f0726 0x21105a00 0xf2d0303 0x37041540 0xc07280f 0x14000014 0x3c140001 0x101000a 0x42dc1e05 0x10000 0x39b21 0x00 0x65 0x20 0x00 0x00 0x00 0x00 0x00 0x00 0x00 0x00 0x680000 0xb0100 0x460f2303 0x181e0f0f 0x3006c00 0x4b00 0x00 0x00 0x00 0x00 0x00 0x00 0x00 0x00 0x00 0x00 0x00 0x00 0x00 0x00 0x00 0x00 0x00 0x00 0x6d 0x09 0x42000500 0x00 0x3006f00 0x1e00 0x32320c 0xc0f0500 0xff000000 0x00 0x1e0033 0x32000000 0x1000000 0x6f00 0x1001e00 0x00 0x00 0x00 0x00 0x00 0x00 0x1000000 0x6f00 0x2001e00 0x32320c 0xc0f0300 0x00 0x00 0x00 0x00 0x1000000 0x7000 0x500 0x00 0x700001 0x50000 0x00 0x71000000 0x3050206 0x730000 0x140000 0x00 0x00 0x00 0x00 0x74 0xff 0x00 0x00 0x00 0x00 0x00 0x00 0x00 0x00 0x00 0x00 0x00 0x00 0x00 0x00 0x00 0x00 0x00 0x00 0x00 0x00 0x00 0x00 0x00 0x00 0x00 0x00 0x00 0x00 0x00 0x00 0x00 0x00 0x00 0x00 0x00 0x00 0x00 0x00 0x00 0x00 0x00 0x00 0x00 0x00 0x00 0x00 0x00 0x00 0x00 0x00 0x00 0x00 0x00 0x00 0x00 0x00 0x00 0x00 0x00 0x00 0x00 0x00 0x00 0x00 0x79000000 0x3000000 0x7c0000 0x70b10 0x1b41 0x64007d00 0x100 >;
				};
			};
		};

		I2C3@0x11010000 {
			compatible = "mediatek,I2C3";
			cell-index = < 0x03 >;
			reg = < 0x11010000 0x1000 >;
			interrupts = < 0x00 0x57 0x08 >;
			def_speed = < 0x82 >;
		};

		SPI1@0x1100A000 {
			compatible = "mediatek,SPI1";
			reg = < 0x1100a000 0x1000 >;
			interrupts = < 0x00 0x76 0x08 >;
			cell-index = < 0x00 >;
		};

		THERM_CTRL@0x1100B000 {
			compatible = "mediatek,THERM_CTRL";
			reg = < 0x1100b000 0x1000 >;
			interrupts = < 0x00 0x4e 0x08 >;
		};

		PTP_FSM@0x1100B000 {
			compatible = "mediatek,PTP_FSM";
			reg = < 0x1100b000 0x1000 >;
			interrupts = < 0x00 0x7d 0x08 >;
		};

		IRDA_FRAMER@0x1100C000 {
			compatible = "mediatek,IRDA_FRAMER";
			reg = < 0x1100c000 0x1000 >;
			interrupts = < 0x00 0x61 0x08 >;
		};

		mt3326-gps@0xffffffff {
			compatible = "mediatek,mt3326-gps";
		};

		NFI@0x1100D000 {
			compatible = "mediatek,NFI";
			reg = < 0x1100d000 0x1000 >;
			interrupts = < 0x00 0x60 0x08 >;
		};

		NFIECC@0x1100E000 {
			compatible = "mediatek,NFIECC";
			reg = < 0x1100e000 0x1000 >;
			interrupts = < 0x00 0x5f 0x08 >;
		};

		NLI_ARB@0x1100F000 {
			compatible = "mediatek,NLI_ARB";
			reg = < 0x1100f000 0x1000 >;
		};

		USB0@0x11200000 {
			compatible = "mediatek,USB0";
			cell-index = < 0x00 >;
			reg = < 0x11200000 0x10000 0x11210000 0x10000 >;
			interrupts = < 0x00 0x49 0x08 >;
			mode = < 0x02 >;
			multipoint = < 0x01 >;
			dyn_fifo = < 0x01 >;
			soft_con = < 0x01 >;
			dma = < 0x01 >;
			num_eps = < 0x10 >;
			dma_channels = < 0x08 >;
		};

		AUDIO@0x11220000 {
			compatible = "mediatek,AUDIO";
			reg = < 0x11220000 0x10000 >;
			interrupts = < 0x00 0x8e 0x08 >;
		};

		MT_SOC_DL1_PCM@0x11220000 {
			compatible = "mediatek,mt_soc_pcm_dl1";
			reg = < 0x11220000 0x1000 >;
			interrupts = < 0x00 0x8e 0x08 >;
		};

		MT_SOC_UL1_PCM@0x11220000 {
			compatible = "mediatek,mt_soc_pcm_capture";
		};

		MT_SOC_HDMI_PCM@0x11220000 {
			compatible = "mediatek,mt_soc_pcm_hdmi";
		};

		MT_SOC_ULDLLOOPBACK_PCM@0x11220000 {
			compatible = "mediatek,mt_soc_pcm_uldlloopback";
		};

		MT_SOC_VOICE@0x11220000 {
			compatible = "mediatek,mt_soc_pcm_voice";
		};

		MT_SOC_VOICE_BT@0x11220000 {
			compatible = "mediatek,mt_soc_pcm_voice_bt";
		};

		MT_SOC_VOICE_EXT@0x11220000 {
			compatible = "mediatek,mt_soc_pcm_voice_ext";
		};

		MT_SOC_VOICE_EXT_BT@0x11220000 {
			compatible = "mediatek,mt_soc_pcm_voice_ext_bt";
		};

		MT_SOC_VOICE_EXTINT@0x11220000 {
			compatible = "mediatek,mt_soc_pcm_voice_extint";
		};

		MT_SOC_VOICE_EXTINT_BT@0x11220000 {
			compatible = "mediatek,mt_soc_pcm_voice_extint_bt";
		};

		MT_SOC_I2S0_PCM@0x11220000 {
			compatible = "mediatek,mt_soc_pcm_dl1_i2s0";
		};

		MT_SOC_MRGRX_PCM@0x11220000 {
			compatible = "mediatek,mt_soc_pcm_mrgrx";
		};

		MT_SOC_MRGRX_AWB_PCM@0x11220000 {
			compatible = "mediatek,mt_soc_pcm_mrgrx_awb";
		};

		MT_SOC_I2S0DL1_PCM@0x11220000 {
			compatible = "mediatek,mt_soc_pcm_dl1_i2s0Dl1";
		};

		MT_SOC_DL1_AWB_PCM@0x11220000 {
			compatible = "mediatek,mt_soc_pcm_dl1_awb";
		};

		MT_SOC_VOIP_BT_OUT@0x11220000 {
			compatible = "mediatek,mt_soc_pcm_dl1_bt";
		};

		MT_SOC_ADC2_ADCI2S2_PCM@0x11220000 {
			compatible = "mediatek,mt_soc_pcm_adc2_adci2s2";
		};

		MT_SOC_VOIP_BT_IN@0x11220000 {
			compatible = "mediatek,mt_soc_pcm_bt_dai";
		};

		MT_SOC_TDMRX_PCM@0x11220000 {
			compatible = "mediatek,mt_soc_tdm_capture";
		};

		MT_SOC_FM_MRGTX_PCM@0x11220000 {
			compatible = "mediatek,mt_soc_pcm_fmtx";
		};

		MT_SOC_UL2_PCM@0x11220000 {
			compatible = "mediatek,mt_soc_pcm_capture2";
		};

		MT_SOC_I2S0_AWB_PCM@0x11220000 {
			compatible = "mediatek,mt_soc_pcm_i2s0_awb";
		};

		MT_SOC_IO2_AWB_PCM@0x11220000 {
			compatible = "mediatek,mt_soc_pcm_io2_awb";
		};

		MT_SOC_MOD_ADCI2S_PCM@0x11220000 {
			compatible = "mediatek,mt_soc_pcm_mod_adci2s";
		};

		MT_SOC_MOD_DAI_PCM@0x11220000 {
			compatible = "mediatek,mt_soc_pcm_mod_dai";
		};

		MT_SOC_ROUTING_PCM@0x11220000 {
			compatible = "mediatek,mt_soc_pcm_routing";
			i2s1clk-gpio = < 0xc1 0x02 >;
			i2s1dat-gpio = < 0xc3 0x02 >;
			i2s1dat1-gpio = < 0xc4 0x02 >;
			i2s1mclk-gpio = < 0xc2 0x02 >;
			i2s1ws-gpio = < 0xc0 0x02 >;
		};

		MT_SOC_HP_IMPEDANCE_PCM@0x11220000 {
			compatible = "mediatek,Mt_soc_pcm_hp_impedance";
		};

		MT_SOC_CODEC_NAME@0x11220000 {
			compatible = "mediatek,mt_soc_codec_63xx";
		};

		MT_SOC_DUMMY_PCM@0x11220000 {
			compatible = "mediatek,mt_soc_pcm_dummy";
		};

		MT_SOC_CODEC_DUMMY_NAME@0x11220000 {
			compatible = "mediatek,mt_soc_codec_dummy";
		};

		MT_SOC_ROUTING_DAI_NAME@0x11220000 {
			compatible = "mediatek,mt_soc_dai_routing";
		};

		MT_SOC_DAI_NAME@0x11220000 {
			compatible = "mediatek,mt_soc_dai_stub";
		};

		MT_SOC_DL2_PCM@0x11220000 {
			compatible = "mediatek,mt_soc_pcm_dl2";
		};

		USB3@0x11270000 {
			compatible = "mediatek,USB3";
			reg = < 0x11270000 0x10000 0x11280000 0x10000 0x11290000 0x10000 >;
			reg-names = "ssusb_base\0ssusb_sif\0ssusb_sif2";
			interrupts = < 0x00 0x7a 0x08 0x00 0x7b 0x08 >;
			interrupt-names = "musb-hdrc\0xhci";
		};

		USB3_XHCI@0x11270000 {
			compatible = "mediatek,USB3_XHCI";
			reg = < 0x11270000 0x10000 0x11280000 0x10000 0x11290000 0x10000 >;
			reg-names = "ssusb_base\0ssusb_sif\0ssusb_sif2";
			interrupts = < 0x00 0x7b 0x08 >;
			iddig-gpio-num = < 0x10 >;
			interrupt-names = "xhci";
		};

		USB3_SIF@0x11280000 {
			compatible = "mediatek,USB3_SIF";
			reg = < 0x11280000 0x10000 >;
		};

		USB3_SIF2@0x11290000 {
			compatible = "mediatek,USB3_SIF2";
			reg = < 0x11290000 0x10000 >;
		};

		BATTERY {
			compatible = "mediatek,battery";
		};

		MFGCFG@0x13FFF000 {
			compatible = "mediatek,MFGCFG";
			reg = < 0x13fff000 0x1000 >;
		};

		HAN@0x13000000 {
			compatible = "mediatek,HAN";
			reg = < 0x13000000 0xffff >;
			interrupts = < 0x00 0xe1 0x08 >;
			interrupt-names = "RGX";
			clock-frequency = < 0x284af100 >;
		};

		MMSYS_CONFIG@0x14000000 {
			compatible = "mediatek,MMSYS_CONFIG";
			reg = < 0x14000000 0x1000 >;
			interrupts = < 0x00 0xcb 0x08 >;
		};

		mdp_rdma0@14001000 {
			compatible = "mediatek,mdp_rdma0";
			reg = < 0x14001000 0x1000 >;
			interrupts = < 0x00 0xb2 0x08 >;
		};

		mdp_rdma1@14002000 {
			compatible = "mediatek,mdp_rdma1";
			reg = < 0x14002000 0x1000 >;
			interrupts = < 0x00 0xb3 0x08 >;
		};

		mdp_rsz0@14003000 {
			compatible = "mediatek,mdp_rsz0";
			reg = < 0x14003000 0x1000 >;
			interrupts = < 0x00 0xb4 0x08 >;
		};

		mdp_rsz1@14004000 {
			compatible = "mediatek,mdp_rsz1";
			reg = < 0x14004000 0x1000 >;
			interrupts = < 0x00 0xb5 0x08 >;
		};

		mdp_rsz2@14005000 {
			compatible = "mediatek,mdp_rsz2";
			reg = < 0x14005000 0x1000 >;
			interrupts = < 0x00 0xb6 0x08 >;
		};

		mdp_wdma@14006000 {
			compatible = "mediatek,mdp_wdma";
			reg = < 0x14006000 0x1000 >;
			interrupts = < 0x00 0xb9 0x08 >;
		};

		mdp_wrot0@14007000 {
			compatible = "mediatek,mdp_wrot0";
			reg = < 0x14007000 0x1000 >;
			interrupts = < 0x00 0xba 0x08 >;
		};

		mdp_wrot1@14008000 {
			compatible = "mediatek,mdp_wrot1";
			reg = < 0x14008000 0x1000 >;
			interrupts = < 0x00 0xbb 0x08 >;
		};

		mdp_tdshp0@14009000 {
			compatible = "mediatek,mdp_tdshp0";
			reg = < 0x14009000 0x1000 >;
			interrupts = < 0x00 0xb7 0x08 >;
		};

		mdp_tdshp1@1400A000 {
			compatible = "mediatek,mdp_tdshp1";
			reg = < 0x1400a000 0x1000 >;
			interrupts = < 0x00 0xb8 0x08 >;
		};

		MDP_CROP@0x1400B000 {
			compatible = "mediatek,MDP_CROP";
			reg = < 0x1400b000 0x1000 >;
		};

		DISPSYS@0x10002000 {
			compatible = "mediatek,DISPSYS";
			reg = < 0x14000000 0x1000 0x1400c000 0x1000 0x1400d000 0x1000 0x1400e000 0x1000 0x1400f000 0x1000 0x14010000 0x1000 0x14011000 0x1000 0x14012000 0x1000 0x14013000 0x1000 0x14014000 0x1000 0x14015000 0x1000 0x14016000 0x1000 0x14017000 0x1000 0x14018000 0x1000 0x14019000 0x1000 0x1401a000 0x1000 0x1401b000 0x1000 0x1401c000 0x1000 0x1401d000 0x1000 0x1401e000 0x1000 0x1401f000 0x1000 0x14020000 0x1000 0x14021000 0x1000 0x14022000 0x1000 0x14023000 0x1000 0x10215000 0x1000 0x10216000 0x1000 >;
			interrupts = < 0x00 0x00 0x08 0x00 0xbc 0x08 0x00 0xbd 0x08 0x00 0xbe 0x08 0x00 0xbf 0x08 0x00 0xc0 0x08 0x00 0xc1 0x08 0x00 0xc2 0x08 0x00 0xc3 0x08 0x00 0xc4 0x08 0x00 0xc5 0x08 0x00 0xc6 0x08 0x00 0x00 0x08 0x00 0x00 0x08 0x00 0x00 0x08 0x00 0xc7 0x08 0x00 0xc8 0x08 0x00 0xc9 0x08 0x00 0xca 0x08 0x00 0x00 0x08 0x00 0x00 0x08 0x00 0xb1 0x08 0x00 0x00 0x08 0x00 0x00 0x08 0x00 0xcc 0x08 0x00 0x8a 0x08 0x00 0x8b 0x08 >;
		};

		DISP_OVL0@0x1400C000 {
			compatible = "mediatek,DISP_OVL0";
			reg = < 0x1400c000 0x1000 >;
		};

		DISP_OVL1@0x1400D000 {
			compatible = "mediatek,DISP_OVL1";
			reg = < 0x1400d000 0x1000 >;
		};

		DISP_RDMA0@0x1400E000 {
			compatible = "mediatek,DISP_RDMA0";
			reg = < 0x1400e000 0x1000 >;
			interrupts = < 0x00 0xbe 0x08 >;
		};

		DISP_RDMA1@0x1400F000 {
			compatible = "mediatek,DISP_RDMA1";
			reg = < 0x1400f000 0x1000 >;
			interrupts = < 0x00 0xbf 0x08 >;
		};

		DISP_RDMA2@0x14010000 {
			compatible = "mediatek,DISP_RDMA2";
			reg = < 0x14010000 0x1000 >;
			interrupts = < 0x00 0xc0 0x08 >;
		};

		DISP_WDMA0@0x14011000 {
			compatible = "mediatek,DISP_WDMA0";
			reg = < 0x14011000 0x1000 >;
			interrupts = < 0x00 0xc1 0x08 >;
		};

		DISP_WDMA1@0x14012000 {
			compatible = "mediatek,DISP_WDMA1";
			reg = < 0x14012000 0x1000 >;
			interrupts = < 0x00 0xc2 0x08 >;
		};

		DISP_COLOR0@0x14013000 {
			compatible = "mediatek,DISP_COLOR0";
			reg = < 0x14013000 0x1000 >;
		};

		DISP_COLOR1@0x14014000 {
			compatible = "mediatek,DISP_COLOR1";
			reg = < 0x14014000 0x1000 >;
		};

		DISP_AAL@0x14015000 {
			compatible = "mediatek,DISP_AAL";
			reg = < 0x14015000 0x1000 >;
			interrupts = < 0x00 0xc5 0x08 >;
		};

		DISP_GAMMA@0x14016000 {
			compatible = "mediatek,DISP_GAMMA";
			reg = < 0x14016000 0x1000 >;
			interrupts = < 0x00 0xc6 0x08 >;
		};

		DISP_MERGE@0x14017000 {
			compatible = "mediatek,DISP_MERGE";
			reg = < 0x14017000 0x1000 >;
		};

		DISP_SPLIT0@0x14018000 {
			compatible = "mediatek,DISP_SPLIT0";
			reg = < 0x14018000 0x1000 >;
		};

		DISP_SPLIT1@0x14019000 {
			compatible = "mediatek,DISP_SPLIT1";
			reg = < 0x14019000 0x1000 >;
		};

		DISP_UFOE@0x1401A000 {
			compatible = "mediatek,DISP_UFOE";
			reg = < 0x1401a000 0x1000 >;
			interrupts = < 0x00 0xc7 0x08 >;
		};

		DSI0@0x1401B000 {
			compatible = "mediatek,DSI0";
			reg = < 0x1401b000 0x1000 >;
			interrupts = < 0x00 0xc8 0x08 >;
		};

		DSI1@0x1401C000 {
			compatible = "mediatek,DSI1";
			reg = < 0x1401c000 0x1000 >;
			interrupts = < 0x00 0xc9 0x08 >;
		};

		DPI@0x1401D000 {
			compatible = "mediatek,DPI";
			reg = < 0x1401d000 0x1000 >;
			interrupts = < 0x00 0xca 0x08 >;
		};

		HDMI@0 {
			compatible = "mediatek,HDMI";
		};

		DISP_PWM0@0x1401E000 {
			compatible = "mediatek,DISP_PWM0";
			reg = < 0x1401e000 0x1000 >;
		};

		DISP_PWM1@0x1401F000 {
			compatible = "mediatek,DISP_PWM1";
			reg = < 0x1401f000 0x1000 >;
		};

		MM_MUTEX@0x14020000 {
			compatible = "mediatek,MM_MUTEX";
			reg = < 0x14020000 0x1000 >;
			interrupts = < 0x00 0xb1 0x08 >;
		};

		SMI_LARB0@0x14021000 {
			compatible = "mediatek,SMI_LARB0";
			reg = < 0x14021000 0x1000 >;
			interrupts = < 0x00 0xcd 0x08 >;
		};

		DISP_OD@0x14023000 {
			compatible = "mediatek,DISP_OD";
			reg = < 0x14023000 0x1000 >;
			interrupts = < 0x00 0xcc 0x08 >;
		};

		ISPSYS@0x15000000 {
			compatible = "mediatek,ISPSYS";
			reg = < 0x15004000 0x9000 0x1500d000 0x1000 0x15000000 0x10000 0x10217000 0x3000 0x10005000 0x1000 >;
			interrupts = < 0x00 0xdb 0x08 0x00 0xdc 0x08 0x00 0xdd 0x08 0x00 0xde 0x08 0x00 0xdf 0x08 >;
		};

		IMGSYS@0x15000000 {
			compatible = "mediatek,IMGSYS";
			reg = < 0x15000000 0x1000 >;
		};

		SMI_LARB2@0x15001000 {
			compatible = "mediatek,SMI_LARB2";
			reg = < 0x15001000 0x1000 >;
			interrupts = < 0x00 0xd9 0x08 >;
		};

		CAM1@0x15004000 {
			compatible = "mediatek,CAM1";
			reg = < 0x15004000 0x1000 >;
			interrupts = < 0x00 0xdd 0x08 >;
		};

		CAM2@0x15005000 {
			compatible = "mediatek,CAM2";
			reg = < 0x15005000 0x1000 >;
		};

		CAM3@0x15006000 {
			compatible = "mediatek,CAM3";
			reg = < 0x15006000 0x1000 >;
		};

		CAM4@0x15007000 {
			compatible = "mediatek,CAM4";
			reg = < 0x15007000 0x1000 >;
		};

		KD_CAMERA_HW1@0x15008000 {
			compatible = "mediatek,CAMERA_HW";
			reg = < 0x15008000 0x1000 >;
		};

		KD_CAMERA_HW2@0x15008000 {
			compatible = "mediatek,CAMERA_HW2";
			reg = < 0x15008000 0x1000 >;
		};

		SENINF@0x15008000 {
			compatible = "mediatek,SENINF";
			reg = < 0x15008000 0x1000 >;
			interrupts = < 0x00 0xda 0x08 >;
		};

		CAMSV@0x15009000 {
			compatible = "mediatek,CAMSV";
			reg = < 0x15009000 0x1000 >;
			interrupts = < 0x00 0xdf 0x08 >;
		};

		FDVT@0x1500B000 {
			compatible = "mediatek,FDVT";
			reg = < 0x1500b000 0x1000 >;
			interrupts = < 0x00 0xe0 0x08 >;
		};

		MIPI_RX@0x1500C000 {
			compatible = "mediatek,MIPI_RX";
			reg = < 0x1500c000 0x1000 >;
		};

		CAM1_INNER@0x1500D000 {
			compatible = "mediatek,CAM1_INNER";
			reg = < 0x1500d000 0x1000 >;
		};

		CAM3_INNER@0x1500E000 {
			compatible = "mediatek,CAM3_INNER";
			reg = < 0x1500e000 0x1000 >;
		};

		CAM4_INNER@0x1500F000 {
			compatible = "mediatek,CAM4_INNER";
			reg = < 0x1500f000 0x1000 >;
		};

		VDEC_GCON@0x16000000 {
			compatible = "mediatek,VDEC_GCON";
			reg = < 0x16000000 0x10000 >;
		};

		SMI_LARB1@16010000 {
			compatible = "mediatek,SMI_LARB1";
			reg = < 0x16010000 0x10000 >;
			interrupts = < 0x00 0xd5 0x08 >;
		};

		VDEC@16020000 {
			compatible = "mediatek,VDEC";
			reg = < 0x16020000 0x10000 >;
			interrupts = < 0x00 0xd4 0x08 >;
		};

		VLD@16021000 {
			compatible = "mediatek,VLD";
			reg = < 0x16021000 0x800 >;
		};

		VLD_TOP@16021800 {
			compatible = "mediatek,VLD_TOP";
			reg = < 0x16021800 0x800 >;
		};

		MC@16022000 {
			compatible = "mediatek,MC";
			reg = < 0x16022000 0x1000 >;
		};

		AVC_VLD@16023000 {
			compatible = "mediatek,AVC_VLD";
			reg = < 0x16023000 0x1000 >;
		};

		AVC_MV@16024000 {
			compatible = "mediatek,AVC_MV";
			reg = < 0x16024000 0x1000 >;
		};

		VDEC_PP@16025000 {
			compatible = "mediatek,VDEC_PP";
			reg = < 0x16025000 0x1000 >;
		};

		VP8_VLD@16026800 {
			compatible = "mediatek,VP8_VLD";
			reg = < 0x16026800 0x800 >;
		};

		VLD2@16027800 {
			compatible = "mediatek,VLD2";
			reg = < 0x16027800 0x800 >;
		};

		HEVC_VLD@16028000 {
			compatible = "mediatek,HEVC_VLD";
			reg = < 0x16028000 0x1000 >;
		};

		MJC_CONFIG@0x17000000 {
			compatible = "mediatek,MJC_CONFIG";
			reg = < 0x17000000 0x1000 >;
			interrupts = < 0x00 0xd8 0x08 >;
		};

		MJC_TOP@0x17001000 {
			compatible = "mediatek,MJC_TOP";
			reg = < 0x17001000 0x1000 >;
			interrupts = < 0x00 0xd7 0x08 >;
		};

		SMI_LARB5@0x17002000 {
			compatible = "mediatek,SMI_LARB5";
			reg = < 0x17002000 0x1000 >;
			interrupts = < 0x00 0xd6 0x08 >;
		};

		VENC_GCON@0x18000000 {
			compatible = "mediatek,VENC_GCON";
			reg = < 0x18000000 0x1000 >;
		};

		SMI_LARB3@0x18001000 {
			compatible = "mediatek,SMI_LARB3";
			reg = < 0x18001000 0x1000 >;
			interrupts = < 0x00 0xcf 0x08 >;
		};

		VENC@0x18002000 {
			compatible = "mediatek,VENC";
			reg = < 0x18002000 0x1000 >;
			interrupts = < 0x00 0xce 0x08 >;
		};

		JPGENC@0x18003000 {
			compatible = "mediatek,JPGENC";
			reg = < 0x18003000 0x1000 >;
			interrupts = < 0x00 0xd0 0x08 >;
		};

		JPGDEC@0x18004000 {
			compatible = "mediatek,JPGDEC";
			reg = < 0x18004000 0x1000 >;
			interrupts = < 0x00 0xd3 0x08 >;
		};

		MD_RGU@0x20050000 {
			compatible = "mediatek,MD_RGU";
			reg = < 0x20050000 0x1000 >;
			interrupts = < 0x00 0xe9 0x02 >;
		};

		MDCLDMA@0x200F0000 {
			compatible = "mediatek,MDCLDMA";
			reg = < 0x200f0000 0x3000 0x200e0000 0x3000 0x1020a000 0x1000 >;
			cell-index = < 0x00 >;
			interrupts = < 0x00 0xea 0x04 0x00 0x8c 0x08 0x00 0xe9 0x02 >;
			cldma,major = < 0xb8 >;
			cldma,minor_base = < 0x00 >;
			cldma,capability = < 0x02 >;
			md_smem_size = < 0x200000 >;
		};

		MTKFB@0 {
			compatible = "mediatek,MTKFB";
		};

		CHIPID@08000000 {
			compatible = "mediatek,CHIPID";
			reg = < 0x8000000 0x04 0x8000004 0x04 0x8000008 0x04 0x800000c 0x04 >;
		};

		fingerprint@ {
			compatible = "mediatek,goodix-fp";
		};

		gpio@0x10001e84 {
			compatible = "mediatek,fpga_gpio";
			reg = < 0x10001e84 0x100 >;
		};
	};

	psci {
		compatible = "arm,psci";
		method = "smc";
		cpu_suspend = < 0x84000001 >;
		cpu_off = < 0x84000002 >;
		cpu_on = < 0x84000003 >;
		affinity_info = < 0x84000004 >;
	};

	MOBICORE {
		compatible = "trustonic,mobicore";
		interrupts = < 0x00 0xf8 0x01 >;
	};

	hwmsensor@0 {
		compatible = "mediatek,hwmsensor";
	};

	gsensor@0 {
		compatible = "mediatek,gsensor";
	};

	als_ps@0 {
		compatible = "mediatek,als_ps";
	};

	m_acc_pl@0 {
		compatible = "mediatek,m_acc_pl";
	};

	m_alsps_pl@0 {
		compatible = "mediatek,m_alsps_pl";
	};

	m_batch_pl@0 {
		compatible = "mediatek,m_batch_pl";
	};

	batchsensor@0 {
		compatible = "mediatek,batchsensor";
	};

	gyroscope@0 {
		compatible = "mediatek,gyroscope";
	};

	m_gyro_pl@0 {
		compatible = "mediatek,m_gyro_pl";
	};

	barometer@0 {
		compatible = "mediatek,barometer";
	};

	m_baro_pl@0 {
		compatible = "mediatek,m_baro_pl";
	};

	msensor@0 {
		compatible = "mediatek,msensor";
	};

	m_mag_pl@0 {
		compatible = "mediatek,m_mag_pl";
	};

	orientation@0 {
		compatible = "mediatek,orientation";
	};

	trusty {
		compatible = "android,trusty-smc-v1";
		ranges;
		#address-cells = < 0x02 >;
		#size-cells = < 0x02 >;

		irq {
			compatible = "android,trusty-irq-v1";
		};

		log {
			compatible = "android,trusty-log-v1";
		};

		virtio {
			compatible = "android,trusty-virtio-v1";
		};
	};
};
